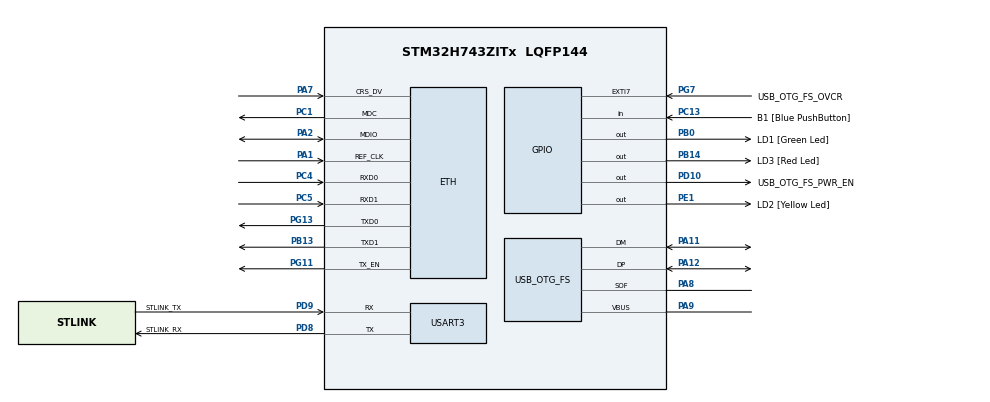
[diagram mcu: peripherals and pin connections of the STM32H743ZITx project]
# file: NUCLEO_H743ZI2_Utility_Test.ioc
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ETH.MediaInterface=HAL_ETH_RMII_MODE
FREERTOS.Tasks01=defaultTask,24,128,StartDefaultTask,Default,NULL,Static,defaultTaskBuffer,defaultTaskControlBlock
FREERTOS.configCHECK_FOR_STACK_OVERFLOW=2
FREERTOS.configRECORD_STACK_HIGH_ADDRESS=1
FREERTOS.configTOTAL_HEAP_SIZE=4096
FREERTOS.configUSE_IDLE_HOOK=1
FREERTOS.configUSE_NEWLIB_REENTRANT=1
Mcu.Family=STM32H7
Mcu.Name=STM32H743ZITx
Mcu.Package=LQFP144
NVIC.PriorityGroup=NVIC_PRIORITYGROUP_4
NVIC.TIM1_UP_IRQn=true\:15\:0\:false\:false\:true\:false\:false\:true\:true
NVIC.TimeBase=TIM1_UP_IRQn
NVIC.TimeBaseIP=TIM1
PA1.Mode=RMII
PA1.Signal=ETH_REF_CLK
PA11.Mode=Device_Only
PA11.Signal=USB_OTG_FS_DM
PA12.Mode=Device_Only
PA12.Signal=USB_OTG_FS_DP
PA2.Mode=RMII
PA2.Signal=ETH_MDIO
PA7.Mode=RMII
PA7.Signal=ETH_CRS_DV
PA8.Mode=Activate_SOF_FS
PA8.Signal=USB_OTG_FS_SOF
PA9.Mode=Activate_VBUS
PA9.Signal=USB_OTG_FS_VBUS
PB0.GPIO_Label=LD1 [Green Led]
PB0.Signal=GPIO_Output
PB13.Mode=RMII
PB13.Signal=ETH_TXD1
PB14.GPIO_Label=LD3 [Red Led]
PB14.Signal=GPIO_Output
PC1.Mode=RMII
PC1.Signal=ETH_MDC
PC13.GPIO_Label=B1 [Blue PushButton]
PC13.Signal=GPIO_Input
PC14-OSC32_IN\ (OSC32_IN).Mode=LSE-External-Oscillator
PC14-OSC32_IN\ (OSC32_IN).Signal=RCC_OSC32_IN
PC15-OSC32_OUT\ (OSC32_OUT).Mode=LSE-External-Oscillator
PC15-OSC32_OUT\ (OSC32_OUT).Signal=RCC_OSC32_OUT
PC4.Mode=RMII
PC4.Signal=ETH_RXD0
PC5.Mode=RMII
PC5.Signal=ETH_RXD1
PD10.GPIO_Label=USB_OTG_FS_PWR_EN
PD10.Signal=GPIO_Output
PD8.GPIO_Label=STLINK_RX
PD8.Mode=Asynchronous
PD8.Signal=USART3_TX
PD9.GPIO_Label=STLINK_TX
PD9.Mode=Asynchronous
PD9.Signal=USART3_RX
PE1.GPIO_Label=LD2 [Yellow Led]
PE1.Signal=GPIO_Output
PG11.Mode=RMII
PG11.Signal=ETH_TX_EN
PG13.Mode=RMII
PG13.Signal=ETH_TXD0
PG7.GPIO_Label=USB_OTG_FS_OVCR
PG7.Signal=GPXTI7
PH0-OSC_IN\ (PH0).Mode=HSE-External-Clock-Source
PH0-OSC_IN\ (PH0).Signal=RCC_OSC_IN
PH1-OSC_OUT\ (PH1).Signal=RCC_OSC_OUT
ProjectManager.HeapSize=0x200
ProjectManager.StackSize=0x400
ProjectManager.TargetToolchain=STM32CubeIDE
RCC.ADCFreq_Value=16125000
RCC.APB1Freq_Value=64000000
RCC.APB2Freq_Value=64000000
RCC.APB3Freq_Value=64000000
RCC.APB4Freq_Value=64000000
RCC.CortexFreq_Value=64000000
RCC.DIVM1=1
RCC.DIVN1=24
RCC.DIVQ1=4
RCC.HCLKFreq_Value=64000000
RCC.HSE_VALUE=8000000
RCC.PLLFRACN=0
RCC.PWR_Regulator_Voltage_Scale=PWR_REGULATOR_VOLTAGE_SCALE2
RCC.SYSCLKFreq_VALUE=64000000
RCC.USBFreq_Value=48000000
USART3.VirtualMode-Asynchronous=VM_ASYNC
USB_OTG_FS.VirtualMode=Device_Only
VP_FREERTOS_VS_CMSIS_V2.Mode=CMSIS_V2
VP_SYS_VS_tim1.Mode=TIM1
board=NUCLEO-H743ZI2

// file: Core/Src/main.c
/* USER CODE BEGIN Header */
/**
  ******************************************************************************
  * @file           : main.c
  * @brief          : Main program body
  ******************************************************************************
  * @attention
  *
  * Copyright (c) 2023 STMicroelectronics.
  * All rights reserved.
  *
  * This software is licensed under terms that can be found in the LICENSE file
  * in the root directory of this software component.
  * If no LICENSE file comes with this software, it is provided AS-IS.
  *
  ******************************************************************************
  */
/* USER CODE END Header */
#include "main.h"
#include "cmsis_os.h"
#include "eth.h"
#include "usart.h"
#include "usb_otg.h"
#include "gpio.h"

/* USER CODE BEGIN Includes */
#include "logging.h"

/* USER CODE END Includes */

/* USER CODE BEGIN PD */
LOG_MODULE("MAIN", LOG_LEVEL_DEFAULT);

/* USER CODE END PD */

void SystemClock_Config(void);
void MX_FREERTOS_Init(void);

int main(void)
{

  /* MCU Configuration--------------------------------------------------------*/

  /* Reset of all peripherals, Initializes the Flash interface and the Systick. */
  HAL_Init();

  /* Configure the system clock */
  SystemClock_Config();

  /* Initialize all configured peripherals */
  MX_GPIO_Init();
  MX_ETH_Init();
  MX_USART3_UART_Init();
  MX_USB_OTG_FS_PCD_Init();

  /* Init scheduler */
  osKernelInitialize();  /* Call init function for freertos objects (in freertos.c) */
  MX_FREERTOS_Init();

  /* Start scheduler */
  osKernelStart();

  /* We should never get here as control is now taken by the scheduler */
  /* Infinite loop */
  while (1)
  {

  }
}

void SystemClock_Config(void)
{
  RCC_OscInitTypeDef RCC_OscInitStruct = {0};
  RCC_ClkInitTypeDef RCC_ClkInitStruct = {0};

  /** Supply configuration update enable
  */
  HAL_PWREx_ConfigSupply(PWR_LDO_SUPPLY);

  /** Configure the main internal regulator output voltage
  */
  __HAL_PWR_VOLTAGESCALING_CONFIG(PWR_REGULATOR_VOLTAGE_SCALE2);

  while(!__HAL_PWR_GET_FLAG(PWR_FLAG_VOSRDY)) {}

  /** Initializes the RCC Oscillators according to the specified parameters
  * in the RCC_OscInitTypeDef structure.
  */
  RCC_OscInitStruct.OscillatorType = RCC_OSCILLATORTYPE_HSI|RCC_OSCILLATORTYPE_HSE;
  RCC_OscInitStruct.HSEState = RCC_HSE_BYPASS;
  RCC_OscInitStruct.HSIState = RCC_HSI_DIV1;
  RCC_OscInitStruct.HSICalibrationValue = RCC_HSICALIBRATION_DEFAULT;
  RCC_OscInitStruct.PLL.PLLState = RCC_PLL_ON;
  RCC_OscInitStruct.PLL.PLLSource = RCC_PLLSOURCE_HSE;
  RCC_OscInitStruct.PLL.PLLM = 1;
  RCC_OscInitStruct.PLL.PLLN = 24;
  RCC_OscInitStruct.PLL.PLLP = 2;
  RCC_OscInitStruct.PLL.PLLQ = 4;
  RCC_OscInitStruct.PLL.PLLR = 2;
  RCC_OscInitStruct.PLL.PLLRGE = RCC_PLL1VCIRANGE_3;
  RCC_OscInitStruct.PLL.PLLVCOSEL = RCC_PLL1VCOWIDE;
  RCC_OscInitStruct.PLL.PLLFRACN = 0;
  if (HAL_RCC_OscConfig(&RCC_OscInitStruct) != HAL_OK)
  {
    Error_Handler();
  }

  /** Initializes the CPU, AHB and APB buses clocks
  */
  RCC_ClkInitStruct.ClockType = RCC_CLOCKTYPE_HCLK|RCC_CLOCKTYPE_SYSCLK
                              |RCC_CLOCKTYPE_PCLK1|RCC_CLOCKTYPE_PCLK2
                              |RCC_CLOCKTYPE_D3PCLK1|RCC_CLOCKTYPE_D1PCLK1;
  RCC_ClkInitStruct.SYSCLKSource = RCC_SYSCLKSOURCE_HSI;
  RCC_ClkInitStruct.SYSCLKDivider = RCC_SYSCLK_DIV1;
  RCC_ClkInitStruct.AHBCLKDivider = RCC_HCLK_DIV1;
  RCC_ClkInitStruct.APB3CLKDivider = RCC_APB3_DIV1;
  RCC_ClkInitStruct.APB1CLKDivider = RCC_APB1_DIV1;
  RCC_ClkInitStruct.APB2CLKDivider = RCC_APB2_DIV1;
  RCC_ClkInitStruct.APB4CLKDivider = RCC_APB4_DIV1;

  if (HAL_RCC_ClockConfig(&RCC_ClkInitStruct, FLASH_LATENCY_1) != HAL_OK)
  {
    Error_Handler();
  }
}

void HAL_TIM_PeriodElapsedCallback(TIM_HandleTypeDef *htim)
{
  if (htim->Instance == TIM1) {
    HAL_IncTick();
  }
}

void Error_Handler(void)
{
  /* USER CODE BEGIN Error_Handler_Debug */
  LOG_ERR("HAL error");
  /* User can add his own implementation to report the HAL error return state */
  __disable_irq();
  while (1)
  {
  }
  /* USER CODE END Error_Handler_Debug */
}

#ifdef  USE_FULL_ASSERT
/**
  * @brief  Reports the name of the source file and the source line number
  *         where the assert_param error has occurred.
  * @param  file: pointer to the source file name
  * @param  line: assert_param error line source number
  * @retval None
  */
void assert_failed(uint8_t *file, uint32_t line)
{
  /* USER CODE BEGIN 6 */
  LOG_WRN("Assertion failed on line %d of %s", line, (char *)file);
  /* USER CODE END 6 */
}
#endif /* USE_FULL_ASSERT */

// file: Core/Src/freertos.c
/* USER CODE BEGIN Header */
/**
  ******************************************************************************
  * File Name          : freertos.c
  * Description        : Code for freertos applications
  ******************************************************************************
  * @attention
  *
  * Copyright (c) 2023 STMicroelectronics.
  * All rights reserved.
  *
  * This software is licensed under terms that can be found in the LICENSE file
  * in the root directory of this software component.
  * If no LICENSE file comes with this software, it is provided AS-IS.
  *
  ******************************************************************************
  */
/* USER CODE END Header */

#include "FreeRTOS.h"
#include "task.h"
#include "main.h"
#include "cmsis_os.h"

/* USER CODE BEGIN Includes */
#include "logging.h"

/* USER CODE END Includes */

typedef StaticTask_t osStaticThreadDef_t;

/* USER CODE BEGIN PD */
LOG_MODULE("FreeRTOS", LOG_LEVEL_DEBUG);

/* USER CODE END PD */

/* Definitions for defaultTask */
osThreadId_t defaultTaskHandle;
uint32_t defaultTaskBuffer[ 128 ];
osStaticThreadDef_t defaultTaskControlBlock;
const osThreadAttr_t defaultTask_attributes = {
  .name = "defaultTask",
  .cb_mem = &defaultTaskControlBlock,
  .cb_size = sizeof(defaultTaskControlBlock),
  .stack_mem = &defaultTaskBuffer[0],
  .stack_size = sizeof(defaultTaskBuffer),
  .priority = (osPriority_t) osPriorityNormal,
};

void StartDefaultTask(void *argument);

void MX_FREERTOS_Init(void); /* (MISRA C 2004 rule 8.1) */

/* Hook prototypes */
void vApplicationIdleHook(void);
void vApplicationStackOverflowHook(xTaskHandle xTask, signed char *pcTaskName);

/* USER CODE BEGIN 2 */
void vApplicationIdleHook( void )
{
   /* vApplicationIdleHook() will only be called if configUSE_IDLE_HOOK is set
   to 1 in FreeRTOSConfig.h. It will be called on each iteration of the idle
   task. It is essential that code added to this hook function never attempts
   to block in any way (for example, call xQueueReceive() with a block time
   specified, or call vTaskDelay()). If the application makes use of the
   vTaskDelete() API function (as this demo application does) then it is also
   important that vApplicationIdleHook() is permitted to return to its calling
   function, because it is the responsibility of the idle task to clean up
   memory allocated by the kernel to any task that has since been deleted. */

   /* Halt the system until the next systick interrupt wakes the device again */
   __WFI();
}
/* USER CODE END 2 */

/* USER CODE BEGIN 4 */
void vApplicationStackOverflowHook(xTaskHandle xTask, signed char *pcTaskName)
{
   /* Run time stack overflow checking is performed if
   configCHECK_FOR_STACK_OVERFLOW is defined to 1 or 2. This hook function is
   called if a stack overflow is detected. */

   LOG_ERR("Stack overflow detected in %s", pcTaskName);
}
/* USER CODE END 4 */

void MX_FREERTOS_Init(void) {

  /* Create the thread(s) */
  /* creation of defaultTask */
  defaultTaskHandle = osThreadNew(StartDefaultTask, NULL, &defaultTask_attributes);

}

void StartDefaultTask(void *argument)
{
  /* USER CODE BEGIN StartDefaultTask */
  /* Infinite loop */
  for(;;)
  {
    osDelay(1000);
    HAL_GPIO_TogglePin(LD1_GPIO_Port, LD1_Pin);
    LOG_DBG("LD1 Pin state %d", HAL_GPIO_ReadPin(LD1_GPIO_Port, LD1_Pin));
  }
  /* USER CODE END StartDefaultTask */
}
